VERSION ""

NS_ :

BS_:

BU_: ECU DAQ_PICO DASH OTHER

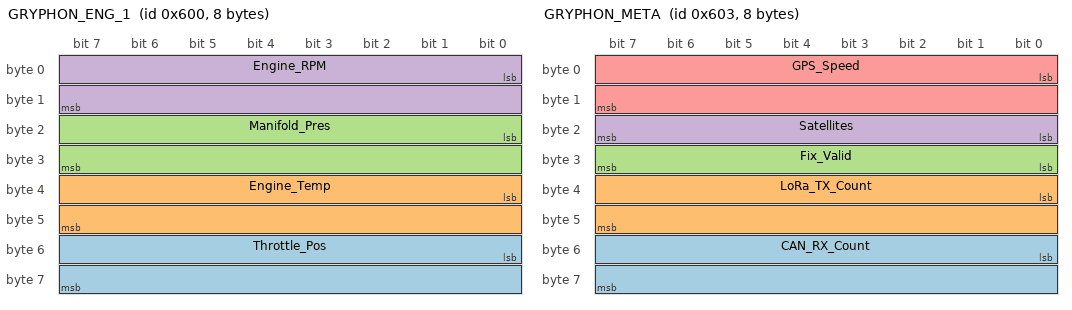
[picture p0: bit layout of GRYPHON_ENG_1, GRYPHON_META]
BO_ 1536 GRYPHON_ENG_1: 8 DAQ_PICO
 SG_ Throttle_Pos : 48|16@1+ (0.1,0.0) [0|100] "%"  DASH
 SG_ Engine_Temp : 32|16@1- (0.1,0.0) [-20|150] "C"  DASH
 SG_ Manifold_Pres : 16|16@1+ (0.1,0.0) [0|300] "kPa"  DASH
 SG_ Engine_RPM : 0|16@1+ (1,0) [0|15000] "RPM"  DASH

BO_ 1537 GRYPHON_ENG_2: 8 DAQ_PICO
 SG_ Air_Temp : 16|16@1- (0.1,0.0) [-20|150] "C"  DASH
 SG_ Battery_Voltage : 0|16@1+ (0.01,0.0) [0|20] "V"  DASH

BO_ 1538 GRYPHON_GPS_POS: 8 DAQ_PICO
 SG_ Longitude : 32|32@1- (1e-07,0.0) [-180|180] "deg"  DASH
 SG_ Latitude : 0|32@1- (1e-07,0.0) [-90|90] "deg"  DASH

BO_ 1539 GRYPHON_META: 8 DAQ_PICO
 SG_ CAN_RX_Count : 48|16@1+ (1,0) [0|65535] "count"  DASH
 SG_ LoRa_TX_Count : 32|16@1+ (1,0) [0|65535] "count"  DASH
 SG_ Fix_Valid : 24|8@1+ (1,0) [0|1] "bool"  DASH
 SG_ Satellites : 16|8@1+ (1,0) [0|50] ""  DASH
 SG_ GPS_Speed : 0|16@1+ (0.1,0.0) [0|300] "kph"  DASH

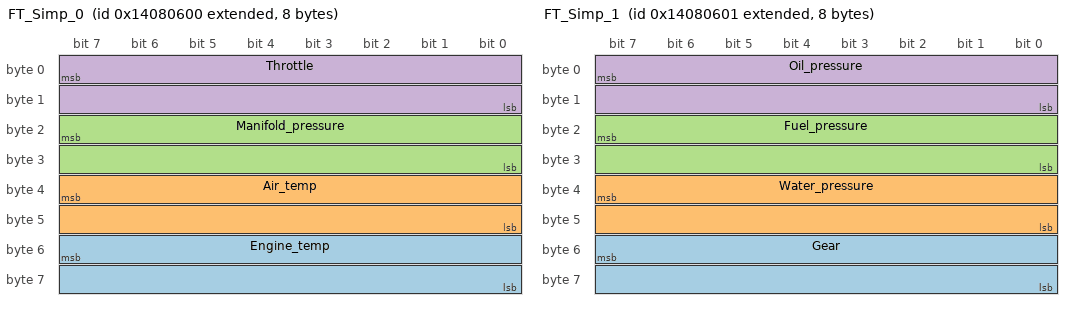
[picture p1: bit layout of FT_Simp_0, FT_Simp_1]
BO_ 2483553792 FT_Simp_0: 8 ECU
 SG_ Engine_temp : 55|16@0- (0.1,0.0) [-20|130] "C"  DAQ_PICO
 SG_ Air_temp : 39|16@0- (0.1,0.0) [-20|80] "C"  DAQ_PICO
 SG_ Manifold_pressure : 23|16@0- (0.001,0.0) [0|3] "bar"  DAQ_PICO
 SG_ Throttle : 7|16@0- (0.1,0.0) [0|100] "%"  DAQ_PICO

BO_ 2483553793 FT_Simp_1: 8 ECU
 SG_ Gear : 55|16@0- (1,0) [-2|10] ""  DAQ_PICO
 SG_ Water_pressure : 39|16@0- (0.001,0.0) [0|5] "bar"  DAQ_PICO
 SG_ Fuel_pressure : 23|16@0- (0.001,0.0) [0|10] "bar"  DAQ_PICO
 SG_ Oil_pressure : 7|16@0- (0.001,0.0) [0|10] "bar"  DAQ_PICO

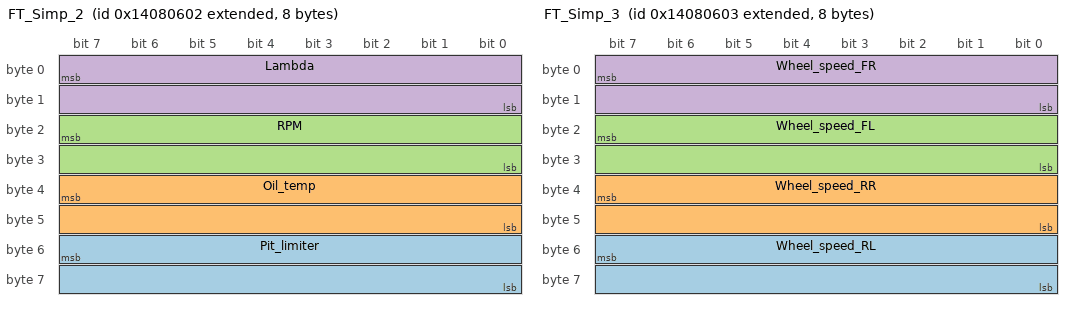
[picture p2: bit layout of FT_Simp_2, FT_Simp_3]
BO_ 2483553794 FT_Simp_2: 8 ECU
 SG_ Pit_limiter : 55|16@0- (1,0) [0|1] ""  DAQ_PICO
 SG_ Oil_temp : 39|16@0- (0.1,0.0) [-20|160] "C"  DAQ_PICO
 SG_ RPM : 23|16@0+ (1,0) [0|15000] "rpm"  DAQ_PICO
 SG_ Lambda : 7|16@0- (0.001,0.0) [0|2] "lambda"  DAQ_PICO

BO_ 2483553795 FT_Simp_3: 8 ECU
 SG_ Wheel_speed_RL : 55|16@0+ (1,0) [0|300] "km/h"  DAQ_PICO
 SG_ Wheel_speed_RR : 39|16@0+ (1,0) [0|300] "km/h"  DAQ_PICO
 SG_ Wheel_speed_FL : 23|16@0+ (1,0) [0|300] "km/h"  DAQ_PICO
 SG_ Wheel_speed_FR : 7|16@0+ (1,0) [0|300] "km/h"  DAQ_PICO

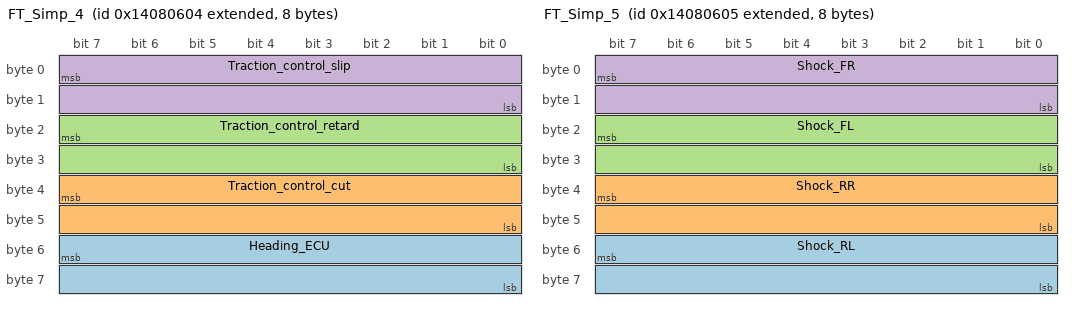
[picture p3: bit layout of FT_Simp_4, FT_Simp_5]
BO_ 2483553796 FT_Simp_4: 8 ECU
 SG_ Heading_ECU : 55|16@0- (1,0) [0|0] ""  DAQ_PICO
 SG_ Traction_control_cut : 39|16@0- (1,0) [0|0] ""  DAQ_PICO
 SG_ Traction_control_retard : 23|16@0- (1,0) [0|0] ""  DAQ_PICO
 SG_ Traction_control_slip : 7|16@0- (1,0) [0|0] ""  DAQ_PICO

BO_ 2483553797 FT_Simp_5: 8 ECU
 SG_ Shock_RL : 55|16@0- (0.001,0.0) [0|5] "V"  DAQ_PICO
 SG_ Shock_RR : 39|16@0- (0.001,0.0) [0|5] "V"  DAQ_PICO
 SG_ Shock_FL : 23|16@0- (0.001,0.0) [0|5] "V"  DAQ_PICO
 SG_ Shock_FR : 7|16@0- (0.001,0.0) [0|5] "V"  DAQ_PICO

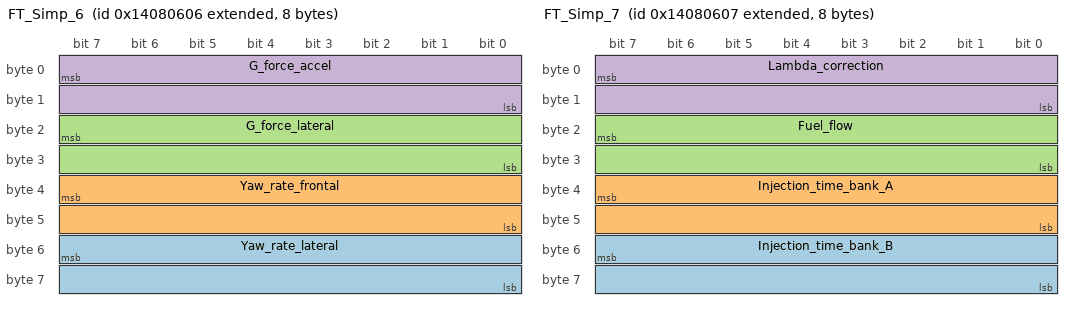
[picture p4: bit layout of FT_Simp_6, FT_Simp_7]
BO_ 2483553798 FT_Simp_6: 8 ECU
 SG_ Yaw_rate_lateral : 55|16@0- (1,0) [0|0] ""  DAQ_PICO
 SG_ Yaw_rate_frontal : 39|16@0- (1,0) [0|0] ""  DAQ_PICO
 SG_ G_force_lateral : 23|16@0- (1,0) [0|0] ""  DAQ_PICO
 SG_ G_force_accel : 7|16@0- (1,0) [0|0] ""  DAQ_PICO

BO_ 2483553799 FT_Simp_7: 8 ECU
 SG_ Injection_time_bank_B : 55|16@0- (0.01,0.0) [0|100] "ms"  DAQ_PICO
 SG_ Injection_time_bank_A : 39|16@0- (0.01,0.0) [0|100] "ms"  DAQ_PICO
 SG_ Fuel_flow : 23|16@0- (0.01,0.0) [0|0] "L/min"  DAQ_PICO
 SG_ Lambda_correction : 7|16@0- (1,0) [0|0] ""  DAQ_PICO

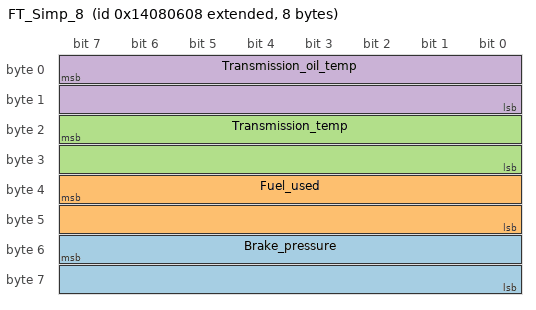
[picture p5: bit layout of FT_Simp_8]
BO_ 2483553800 FT_Simp_8: 8 ECU
 SG_ Brake_pressure : 55|16@0- (0.001,0.0) [0|200] "bar"  DAQ_PICO
 SG_ Fuel_used : 39|16@0- (1,0) [0|0] "L"  DAQ_PICO
 SG_ Transmission_temp : 23|16@0- (0.1,0.0) [-20|160] "C"  DAQ_PICO
 SG_ Transmission_oil_temp : 7|16@0- (0.1,0.0) [-20|160] "C"  DAQ_PICO

CM_ SG_ 2483553796 Heading_ECU "ftcan_packet.dbc says x0.1 deg";
CM_ SG_ 2483553796 Traction_control_retard "ftcan_packet.dbc says x0.1 deg";
CM_ SG_ 2483553798 Yaw_rate_lateral "ftcan_packet.dbc says x0.1 deg/s";
CM_ SG_ 2483553798 Yaw_rate_frontal "ftcan_packet.dbc says x0.1 deg/s";
CM_ SG_ 2483553798 G_force_lateral "ftcan_packet.dbc says x0.01 G";
CM_ SG_ 2483553798 G_force_accel "ftcan_packet.dbc says x0.01 G";
CM_ SG_ 2483553799 Fuel_flow "ftcan_packet.dbc says x0.1 L/h";
CM_ SG_ 2483553799 Lambda_correction "ftcan_packet.dbc says x0.1 %";
CM_ SG_ 2483553800 Transmission_oil_temp "ftcan_packet.dbc calls this Oil_Temp_2";
BA_DEF_ BO_  "GenMsgCycleTime" INT 0 65535;
BA_DEF_DEF_  "GenMsgCycleTime" 0;
BA_ "GenMsgCycleTime" BO_ 1536 50;
BA_ "GenMsgCycleTime" BO_ 1537 50;
BA_ "GenMsgCycleTime" BO_ 1538 50;
BA_ "GenMsgCycleTime" BO_ 1539 50;
